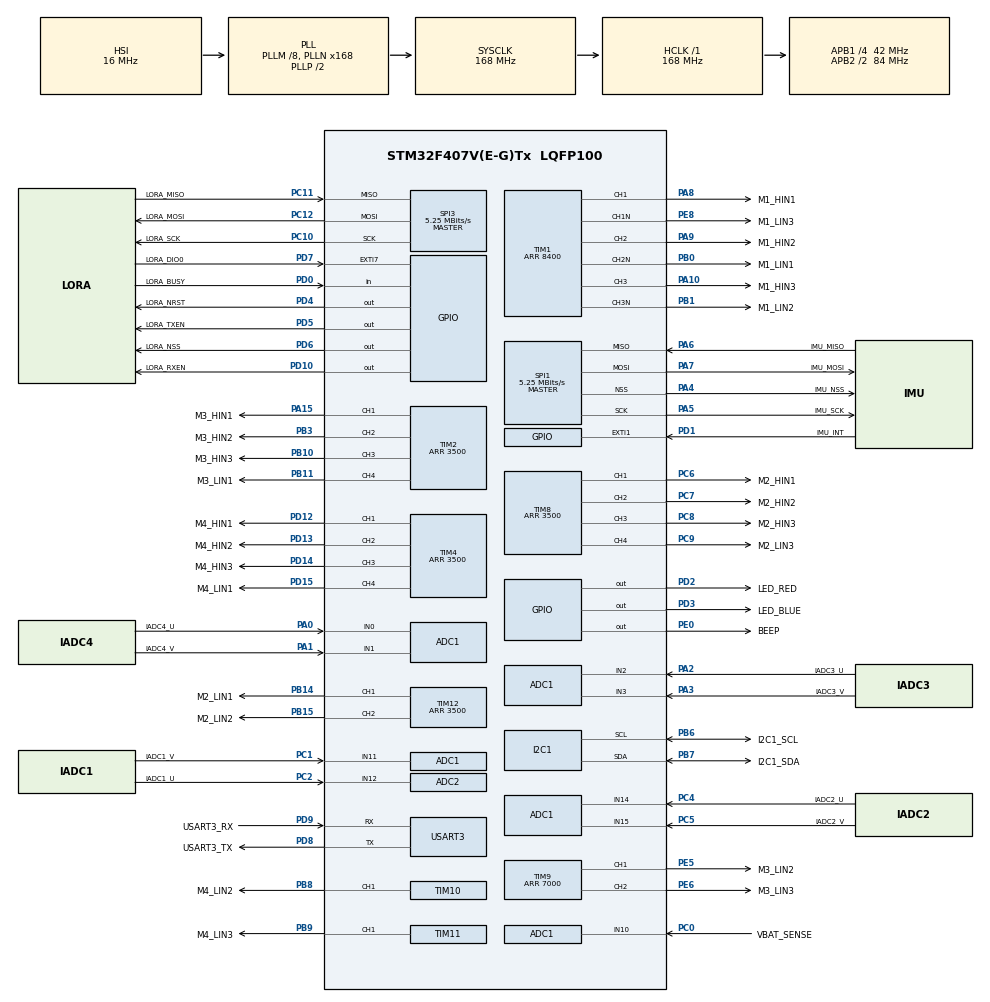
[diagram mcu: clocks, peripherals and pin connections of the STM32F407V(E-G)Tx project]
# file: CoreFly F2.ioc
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ADC1.Channel-9\#ChannelRegularConversion=ADC_CHANNEL_10
ADC1.ClockPrescaler=ADC_CLOCK_SYNC_PCLK_DIV4
ADC1.NbrOfConversionFlag=1
ADC1.Rank-9\#ChannelRegularConversion=1
ADC1.SamplingTime-9\#ChannelRegularConversion=ADC_SAMPLETIME_15CYCLES
ADC1.master=1
ADC2.Channel-0\#ChannelRegularConversion=ADC_CHANNEL_12
ADC2.ClockPrescaler=ADC_CLOCK_SYNC_PCLK_DIV4
ADC2.NbrOfConversionFlag=1
ADC2.Rank-0\#ChannelRegularConversion=1
ADC2.SamplingTime-0\#ChannelRegularConversion=ADC_SAMPLETIME_15CYCLES
I2C1.DutyCycle=I2C_DUTYCYCLE_16_9
I2C1.I2C_Mode=I2C_Fast
Mcu.Family=STM32F4
Mcu.Name=STM32F407V(E-G)Tx
Mcu.Package=LQFP100
NVIC.EXTI1_IRQn=true\:5\:0\:true\:false\:true\:true\:true\:true
NVIC.EXTI9_5_IRQn=true\:0\:0\:false\:false\:true\:true\:true\:true
NVIC.PriorityGroup=NVIC_PRIORITYGROUP_4
PA0-WKUP.GPIO_Label=IADC4_U
PA0-WKUP.Signal=ADCx_IN0
PA1.GPIO_Label=IADC4_V
PA1.Signal=ADCx_IN1
PA10.GPIO_Label=M1_HIN3
PA10.Signal=S_TIM1_CH3
PA13.Mode=Serial_Wire
PA13.Signal=SYS_JTMS-SWDIO
PA14.Mode=Serial_Wire
PA14.Signal=SYS_JTCK-SWCLK
PA15.GPIO_Label=M3_HIN1
PA15.Signal=S_TIM2_CH1_ETR
PA2.GPIO_Label=IADC3_U
PA2.Signal=ADCx_IN2
PA3.GPIO_Label=IADC3_V
PA3.Signal=ADCx_IN3
PA4.GPIO_Label=IMU_NSS
PA4.Mode=NSS_Signal_Hard_Output
PA4.Signal=SPI1_NSS
PA5.GPIO_Label=IMU_SCK
PA5.Mode=Full_Duplex_Master
PA5.Signal=SPI1_SCK
PA6.GPIO_Label=IMU_MISO
PA6.Mode=Full_Duplex_Master
PA6.Signal=SPI1_MISO
PA7.GPIO_Label=IMU_MOSI
PA7.Mode=Full_Duplex_Master
PA7.Signal=SPI1_MOSI
PA8.GPIO_Label=M1_HIN1
PA8.Signal=S_TIM1_CH1
PA9.GPIO_Label=M1_HIN2
PA9.Signal=S_TIM1_CH2
PB0.GPIO_Label=M1_LIN1
PB0.Mode=PWM Generation2 CH2 CH2N
PB0.Signal=TIM1_CH2N
PB1.GPIO_Label=M1_LIN2
PB1.Mode=PWM Generation3 CH3 CH3N
PB1.Signal=TIM1_CH3N
PB10.GPIO_Label=M3_HIN3
PB10.Signal=S_TIM2_CH3
PB11.GPIO_Label=M3_LIN1
PB11.Signal=S_TIM2_CH4
PB14.GPIO_Label=M2_LIN1
PB14.Signal=S_TIM12_CH1
PB15.GPIO_Label=M2_LIN2
PB15.Signal=S_TIM12_CH2
PB3.GPIO_Label=M3_HIN2
PB3.Signal=S_TIM2_CH2
PB6.GPIO_Label=I2C1_SCL
PB6.GPIO_Pu=GPIO_PULLUP
PB6.Mode=I2C
PB6.Signal=I2C1_SCL
PB7.GPIO_Label=I2C1_SDA
PB7.GPIO_Pu=GPIO_PULLUP
PB7.Mode=I2C
PB7.Signal=I2C1_SDA
PB8.GPIO_Label=M4_LIN2
PB8.Signal=S_TIM10_CH1
PB9.GPIO_Label=M4_LIN3
PB9.Signal=S_TIM11_CH1
PC0.GPIO_Label=VBAT_SENSE
PC0.Signal=ADCx_IN10
PC1.GPIO_Label=IADC1_V
PC1.Signal=ADCx_IN11
PC10.GPIO_Label=LORA_SCK
PC10.Mode=Full_Duplex_Master
PC10.Signal=SPI3_SCK
PC11.GPIO_Label=LORA_MISO
PC11.Mode=Full_Duplex_Master
PC11.Signal=SPI3_MISO
PC12.GPIO_Label=LORA_MOSI
PC12.Mode=Full_Duplex_Master
PC12.Signal=SPI3_MOSI
PC2.GPIO_Label=IADC1_U
PC2.Signal=ADCx_IN12
PC4.GPIO_Label=IADC2_U
PC4.Signal=ADCx_IN14
PC5.GPIO_Label=IADC2_V
PC5.Signal=ADCx_IN15
PC6.GPIO_Label=M2_HIN1
PC6.Signal=S_TIM8_CH1
PC7.GPIO_Label=M2_HIN2
PC7.Signal=S_TIM8_CH2
PC8.GPIO_Label=M2_HIN3
PC8.Signal=S_TIM8_CH3
PC9.GPIO_Label=M2_LIN3
PC9.Signal=S_TIM8_CH4
PD0.GPIO_Label=LORA_BUSY
PD0.Signal=GPIO_Input
PD1.GPIO_Label=IMU_INT
PD1.GPIO_PuPd=GPIO_PULLDOWN
PD1.Signal=GPXTI1
PD10.GPIO_Label=LORA_RXEN
PD10.PinState=GPIO_PIN_SET
PD10.Signal=GPIO_Output
PD12.GPIO_Label=M4_HIN1
PD12.Signal=S_TIM4_CH1
PD13.GPIO_Label=M4_HIN2
PD13.Signal=S_TIM4_CH2
PD14.GPIO_Label=M4_HIN3
PD14.Signal=S_TIM4_CH3
PD15.GPIO_Label=M4_LIN1
PD15.Signal=S_TIM4_CH4
PD2.GPIO_Label=LED_RED
PD2.PinState=GPIO_PIN_SET
PD2.Signal=GPIO_Output
PD3.GPIO_Label=LED_BLUE
PD3.PinState=GPIO_PIN_SET
PD3.Signal=GPIO_Output
PD4.GPIO_Label=LORA_NRST
PD4.PinState=GPIO_PIN_SET
PD4.Signal=GPIO_Output
PD5.GPIO_Label=LORA_TXEN
PD5.Signal=GPIO_Output
PD6.GPIO_Label=LORA_NSS
PD6.PinState=GPIO_PIN_SET
PD6.Signal=GPIO_Output
PD7.GPIO_Label=LORA_DIO0
PD7.Signal=GPXTI7
PD8.GPIO_Label=USART3_TX
PD8.Mode=Asynchronous
PD8.Signal=USART3_TX
PD9.GPIO_Label=USART3_RX
PD9.Mode=Asynchronous
PD9.Signal=USART3_RX
PE0.GPIO_Label=BEEP
PE0.GPIO_PuPd=GPIO_PULLUP
PE0.PinState=GPIO_PIN_SET
PE0.Signal=GPIO_Output
PE5.GPIO_Label=M3_LIN2
PE5.Signal=S_TIM9_CH1
PE6.GPIO_Label=M3_LIN3
PE6.Signal=S_TIM9_CH2
PE8.GPIO_Label=M1_LIN3
PE8.Mode=PWM Generation1 CH1 CH1N
PE8.Signal=TIM1_CH1N
PH0-OSC_IN.Mode=HSE-External-Oscillator
PH0-OSC_IN.Signal=RCC_OSC_IN
PH1-OSC_OUT.Mode=HSE-External-Oscillator
PH1-OSC_OUT.Signal=RCC_OSC_OUT
ProjectManager.HeapSize=0x200
ProjectManager.StackSize=0x400
ProjectManager.TargetToolchain=MDK-ARM V5.32
RCC.48MHZClocksFreq_Value=84000000
RCC.AHBFreq_Value=168000000
RCC.APB1CLKDivider=RCC_HCLK_DIV4
RCC.APB1Freq_Value=42000000
RCC.APB1TimFreq_Value=84000000
RCC.APB2CLKDivider=RCC_HCLK_DIV2
RCC.APB2Freq_Value=84000000
RCC.APB2TimFreq_Value=168000000
RCC.CortexFreq_Value=168000000
RCC.HCLKFreq_Value=168000000
RCC.HSE_VALUE=8000000
RCC.HSI_VALUE=16000000
RCC.LSE_VALUE=32768
RCC.PLLM=8
RCC.PLLN=168
RCC.SYSCLKFreq_VALUE=168000000
RCC.SYSCLKSource=RCC_SYSCLKSOURCE_PLLCLK
RCC.VCOOutputFreq_Value=336000000
SH.ADCx_IN0.0=ADC1_IN0,IN0
SH.ADCx_IN1.0=ADC1_IN1,IN1
SH.ADCx_IN10.0=ADC1_IN10,IN10
SH.ADCx_IN11.0=ADC1_IN11,IN11
SH.ADCx_IN12.0=ADC2_IN12,IN12
SH.ADCx_IN14.0=ADC1_IN14,IN14
SH.ADCx_IN15.0=ADC1_IN15,IN15
SH.ADCx_IN2.0=ADC1_IN2,IN2
SH.ADCx_IN3.0=ADC1_IN3,IN3
SH.S_TIM10_CH1.0=TIM10_CH1,PWM Generation1 CH1
SH.S_TIM11_CH1.0=TIM11_CH1,PWM Generation1 CH1
SH.S_TIM12_CH1.0=TIM12_CH1,PWM Generation1 CH1
SH.S_TIM12_CH2.0=TIM12_CH2,PWM Generation2 CH2
SH.S_TIM1_CH1.0=TIM1_CH1,PWM Generation1 CH1 CH1N
SH.S_TIM1_CH2.0=TIM1_CH2,PWM Generation2 CH2 CH2N
SH.S_TIM1_CH3.0=TIM1_CH3,PWM Generation3 CH3 CH3N
SH.S_TIM2_CH1_ETR.0=TIM2_CH1,PWM Generation1 CH1
SH.S_TIM2_CH2.0=TIM2_CH2,PWM Generation2 CH2
SH.S_TIM2_CH3.0=TIM2_CH3,PWM Generation3 CH3
SH.S_TIM2_CH4.0=TIM2_CH4,PWM Generation4 CH4
SH.S_TIM4_CH1.0=TIM4_CH1,PWM Generation1 CH1
SH.S_TIM4_CH2.0=TIM4_CH2,PWM Generation2 CH2
SH.S_TIM4_CH3.0=TIM4_CH3,PWM Generation3 CH3
SH.S_TIM4_CH4.0=TIM4_CH4,PWM Generation4 CH4
SH.S_TIM8_CH1.0=TIM8_CH1,PWM Generation1 CH1
SH.S_TIM8_CH2.0=TIM8_CH2,PWM Generation2 CH2
SH.S_TIM8_CH3.0=TIM8_CH3,PWM Generation3 CH3
SH.S_TIM8_CH4.0=TIM8_CH4,PWM Generation4 CH4
SH.S_TIM9_CH1.0=TIM9_CH1,PWM Generation1 CH1
SH.S_TIM9_CH2.0=TIM9_CH2,PWM Generation2 CH2
SPI1.BaudRatePrescaler=SPI_BAUDRATEPRESCALER_16
SPI1.CalculateBaudRate=5.25 MBits/s
SPI1.Direction=SPI_DIRECTION_2LINES
SPI1.Mode=SPI_MODE_MASTER
SPI1.VirtualNSS=VM_NSSHARD
SPI1.VirtualType=VM_MASTER
SPI3.BaudRatePrescaler=SPI_BAUDRATEPRESCALER_8
SPI3.CalculateBaudRate=5.25 MBits/s
SPI3.Direction=SPI_DIRECTION_2LINES
SPI3.Mode=SPI_MODE_MASTER
SPI3.VirtualType=VM_MASTER
TIM1.AutoReloadPreload=TIM_AUTORELOAD_PRELOAD_ENABLE
TIM1.Channel-PWM\ Generation1\ CH1\ CH1N=TIM_CHANNEL_1
TIM1.Channel-PWM\ Generation2\ CH2\ CH2N=TIM_CHANNEL_2
TIM1.Channel-PWM\ Generation3\ CH3\ CH3N=TIM_CHANNEL_3
TIM1.CounterMode=TIM_COUNTERMODE_CENTERALIGNED1
TIM1.DeadTime=150
TIM1.Period=8400
TIM10.Channel=TIM_CHANNEL_1
TIM10.Period=3500
TIM11.Channel=TIM_CHANNEL_1
TIM11.Period=3500
TIM12.Channel-PWM\ Generation1\ CH1=TIM_CHANNEL_1
TIM12.Channel-PWM\ Generation2\ CH2=TIM_CHANNEL_2
TIM12.Period=3500
TIM2.Channel-PWM\ Generation1\ CH1=TIM_CHANNEL_1
TIM2.Channel-PWM\ Generation2\ CH2=TIM_CHANNEL_2
TIM2.Channel-PWM\ Generation3\ CH3=TIM_CHANNEL_3
TIM2.Channel-PWM\ Generation4\ CH4=TIM_CHANNEL_4
TIM2.Period=3500
TIM4.Channel-PWM\ Generation1\ CH1=TIM_CHANNEL_1
TIM4.Channel-PWM\ Generation2\ CH2=TIM_CHANNEL_2
TIM4.Channel-PWM\ Generation3\ CH3=TIM_CHANNEL_3
TIM4.Channel-PWM\ Generation4\ CH4=TIM_CHANNEL_4
TIM4.Period=3500
TIM8.Channel-PWM\ Generation1\ CH1=TIM_CHANNEL_1
TIM8.Channel-PWM\ Generation2\ CH2=TIM_CHANNEL_2
TIM8.Channel-PWM\ Generation3\ CH3=TIM_CHANNEL_3
TIM8.Channel-PWM\ Generation4\ CH4=TIM_CHANNEL_4
TIM8.CounterMode=TIM_COUNTERMODE_CENTERALIGNED1
TIM8.Period=3500
TIM9.Channel-PWM\ Generation1\ CH1=TIM_CHANNEL_1
TIM9.Channel-PWM\ Generation2\ CH2=TIM_CHANNEL_2
TIM9.Period=7000
USART3.VirtualMode=VM_ASYNC
VP_TIM10_VS_ClockSourceINT.Mode=Enable_Timer
VP_TIM11_VS_ClockSourceINT.Mode=Enable_Timer
board=custom

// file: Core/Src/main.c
/* USER CODE BEGIN Header */
/**
  ******************************************************************************
  * @file           : main.c
  * @brief          : Main program body
  ******************************************************************************
  * @attention
  *
  * Copyright (c) 2026 STMicroelectronics.
  * All rights reserved.
  *
  * This software is licensed under terms that can be found in the LICENSE file
  * in the root directory of this software component.
  * If no LICENSE file comes with this software, it is provided AS-IS.
  *
  ******************************************************************************
  */
/* USER CODE END Header */
#include "main.h"
#include "adc.h"
#include "i2c.h"
#include "spi.h"
#include "tim.h"
#include "usart.h"
#include "gpio.h"

/* USER CODE BEGIN Includes */
#include <stdio.h>
#include <math.h>
#include "BSP_USART.h"
#include "App_FreeRTOS.h"
/* USER CODE END Includes */

void SystemClock_Config(void);

int main(void)
{

  /* MCU Configuration--------------------------------------------------------*/

  /* Reset of all peripherals, Initializes the Flash interface and the Systick. */
  HAL_Init();

  /* Configure the system clock */
  SystemClock_Config();

  /* Initialize all configured peripherals */
  MX_GPIO_Init();
  MX_TIM1_Init();
  MX_ADC1_Init();
  MX_ADC2_Init();
  MX_TIM2_Init();
  MX_TIM4_Init();
  MX_TIM9_Init();
  MX_I2C1_Init();
  MX_SPI3_Init();
  MX_SPI1_Init();
  MX_TIM8_Init();
  MX_TIM10_Init();
  MX_TIM11_Init();
  MX_TIM12_Init();
  MX_USART3_UART_Init();
  /* USER CODE BEGIN 2 */
  // HAL_UART_Transmit(&huart1, (uint8_t *)"Hello World!\n", 13, 1000);

  App_FreeRTOS_start(); // ����FreeRTOS����
  // printf("Hello World!\n");

  /* USER CODE END 2 */

  /* Infinite loop */
  while (1)
  {

  }
}

void SystemClock_Config(void)
{
  RCC_OscInitTypeDef RCC_OscInitStruct = {0};
  RCC_ClkInitTypeDef RCC_ClkInitStruct = {0};

  /** Configure the main internal regulator output voltage
  */
  __HAL_RCC_PWR_CLK_ENABLE();
  __HAL_PWR_VOLTAGESCALING_CONFIG(PWR_REGULATOR_VOLTAGE_SCALE1);

  /** Initializes the RCC Oscillators according to the specified parameters
  * in the RCC_OscInitTypeDef structure.
  */
  RCC_OscInitStruct.OscillatorType = RCC_OSCILLATORTYPE_HSI;
  RCC_OscInitStruct.HSIState = RCC_HSI_ON;
  RCC_OscInitStruct.HSICalibrationValue = RCC_HSICALIBRATION_DEFAULT;
  RCC_OscInitStruct.PLL.PLLState = RCC_PLL_ON;
  RCC_OscInitStruct.PLL.PLLSource = RCC_PLLSOURCE_HSI;
  RCC_OscInitStruct.PLL.PLLM = 8;
  RCC_OscInitStruct.PLL.PLLN = 168;
  RCC_OscInitStruct.PLL.PLLP = RCC_PLLP_DIV2;
  RCC_OscInitStruct.PLL.PLLQ = 4;
  if (HAL_RCC_OscConfig(&RCC_OscInitStruct) != HAL_OK)
  {
    Error_Handler();
  }

  /** Initializes the CPU, AHB and APB buses clocks
  */
  RCC_ClkInitStruct.ClockType = RCC_CLOCKTYPE_HCLK|RCC_CLOCKTYPE_SYSCLK
                              |RCC_CLOCKTYPE_PCLK1|RCC_CLOCKTYPE_PCLK2;
  RCC_ClkInitStruct.SYSCLKSource = RCC_SYSCLKSOURCE_PLLCLK;
  RCC_ClkInitStruct.AHBCLKDivider = RCC_SYSCLK_DIV1;
  RCC_ClkInitStruct.APB1CLKDivider = RCC_HCLK_DIV4;
  RCC_ClkInitStruct.APB2CLKDivider = RCC_HCLK_DIV2;

  if (HAL_RCC_ClockConfig(&RCC_ClkInitStruct, FLASH_LATENCY_5) != HAL_OK)
  {
    Error_Handler();
  }
}

void Error_Handler(void)
{
  __disable_irq();
  while (1)
  {
  }
}
